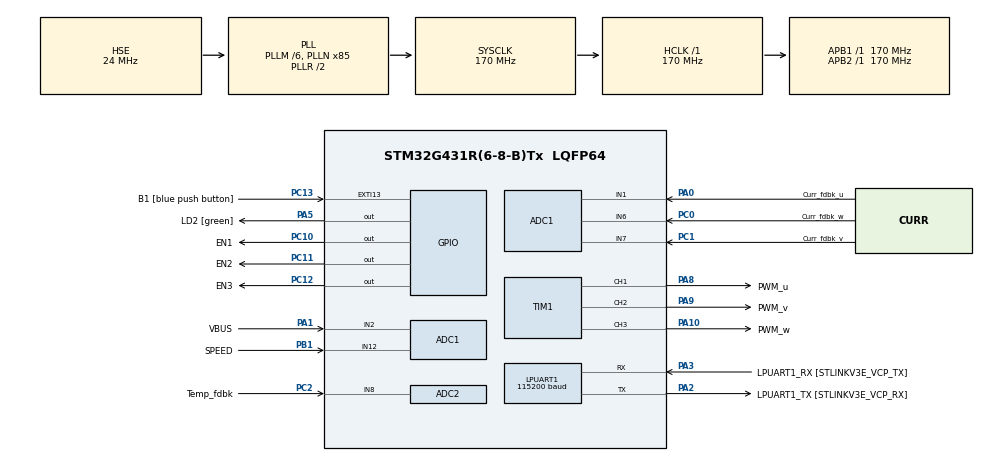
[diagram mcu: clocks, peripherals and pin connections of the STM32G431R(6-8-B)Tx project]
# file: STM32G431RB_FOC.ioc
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ADC1.Channel-0\#ChannelRegularConversion=ADC_CHANNEL_1
ADC1.EnableInjectedConversion=ENABLE
ADC1.ExternalTrigInjecConv=ADC_EXTERNALTRIGINJEC_T1_TRGO
ADC1.InjNumberOfConversion=3
ADC1.InjectedChannel-1\#ChannelInjectedConversion=ADC_CHANNEL_1
ADC1.InjectedChannel-2\#ChannelInjectedConversion=ADC_CHANNEL_7
ADC1.InjectedChannel-3\#ChannelInjectedConversion=ADC_CHANNEL_6
ADC1.InjectedOffsetNumber-1\#ChannelInjectedConversion=ADC_OFFSET_NONE
ADC1.InjectedOffsetNumber-2\#ChannelInjectedConversion=ADC_OFFSET_NONE
ADC1.InjectedOffsetNumber-3\#ChannelInjectedConversion=ADC_OFFSET_NONE
ADC1.InjectedRank-1\#ChannelInjectedConversion=1
ADC1.InjectedRank-2\#ChannelInjectedConversion=2
ADC1.InjectedRank-3\#ChannelInjectedConversion=3
ADC1.InjectedSamplingTime-1\#ChannelInjectedConversion=ADC_SAMPLETIME_2CYCLES_5
ADC1.InjectedSamplingTime-2\#ChannelInjectedConversion=ADC_SAMPLETIME_2CYCLES_5
ADC1.InjectedSamplingTime-3\#ChannelInjectedConversion=ADC_SAMPLETIME_2CYCLES_5
ADC1.NbrOfConversionFlag=1
ADC1.OffsetNumber-0\#ChannelRegularConversion=ADC_OFFSET_NONE
ADC1.Rank-0\#ChannelRegularConversion=1
ADC1.Rank1_Channel=ADC_CHANNEL_1
ADC1.Rank2_Channel=ADC_CHANNEL_7
ADC1.Rank3_Channel=ADC_CHANNEL_6
ADC1.SamplingTime-0\#ChannelRegularConversion=ADC_SAMPLETIME_2CYCLES_5
ADC1.master=1
ADC2.Channel-0\#ChannelRegularConversion=ADC_CHANNEL_8
ADC2.NbrOfConversionFlag=1
ADC2.OffsetNumber-0\#ChannelRegularConversion=ADC_OFFSET_NONE
ADC2.Rank-0\#ChannelRegularConversion=1
ADC2.SamplingTime-0\#ChannelRegularConversion=ADC_SAMPLETIME_2CYCLES_5
LPUART1.BaudRate=115200
LPUART1.WordLength=UART_WORDLENGTH_8B
Mcu.Family=STM32G4
Mcu.Name=STM32G431R(6-8-B)Tx
Mcu.Package=LQFP64
NVIC.PriorityGroup=NVIC_PRIORITYGROUP_4
PA0.GPIO_Label=Curr_fdbk_u
PA0.Mode=IN1-Single-Ended
PA0.Signal=ADC1_IN1
PA1.GPIO_Label=VBUS
PA1.Mode=IN2-Single-Ended
PA1.Signal=ADC1_IN2
PA10.GPIO_Label=PWM_w
PA10.Signal=S_TIM1_CH3
PA13.GPIO_Label=T_SWDIO
PA13.Mode=Serial_Wire
PA13.Signal=SYS_JTMS-SWDIO
PA14.GPIO_Label=T_SWCLK
PA14.Mode=Serial_Wire
PA14.Signal=SYS_JTCK-SWCLK
PA2.GPIO_Label=LPUART1_TX [STLINKV3E_VCP_RX]
PA2.Mode=Asynchronous
PA2.Signal=LPUART1_TX
PA3.GPIO_Label=LPUART1_RX [STLINKV3E_VCP_TX]
PA3.Mode=Asynchronous
PA3.Signal=LPUART1_RX
PA5.GPIO_Label=LD2 [green]
PA5.Signal=GPIO_Output
PA8.GPIO_Label=PWM_u
PA8.Signal=S_TIM1_CH1
PA9.GPIO_Label=PWM_v
PA9.Signal=S_TIM1_CH2
PB1.GPIO_Label=SPEED
PB1.Mode=IN12-Single-Ended
PB1.Signal=ADC1_IN12
PB3.GPIO_Label=T_SWO
PB3.Signal=SYS_JTDO-SWO
PC0.GPIO_Label=Curr_fdbk_w
PC0.Mode=IN6-Single-Ended
PC0.Signal=ADC1_IN6
PC1.GPIO_Label=Curr_fdbk_v
PC1.Mode=IN7-Single-Ended
PC1.Signal=ADC1_IN7
PC10.GPIO_Label=EN1
PC10.Signal=GPIO_Output
PC11.GPIO_Label=EN2
PC11.Signal=GPIO_Output
PC12.GPIO_Label=EN3
PC12.Signal=GPIO_Output
PC13.GPIO_Label=B1 [blue push button]
PC13.Signal=GPXTI13
PC14-OSC32_IN.Mode=LSE-External-Oscillator
PC14-OSC32_IN.Signal=RCC_OSC32_IN
PC15-OSC32_OUT.Mode=LSE-External-Oscillator
PC15-OSC32_OUT.Signal=RCC_OSC32_OUT
PC2.GPIO_Label=Temp_fdbk
PC2.Mode=IN8-Single-Ended
PC2.Signal=ADC2_IN8
PF0-OSC_IN.Mode=HSE-External-Oscillator
PF0-OSC_IN.Signal=RCC_OSC_IN
PF1-OSC_OUT.Mode=HSE-External-Oscillator
PF1-OSC_OUT.Signal=RCC_OSC_OUT
ProjectManager.HeapSize=0x200
ProjectManager.StackSize=0x400
ProjectManager.TargetToolchain=Makefile
RCC.ADC12Freq_Value=170000000
RCC.AHBFreq_Value=170000000
RCC.APB1Freq_Value=170000000
RCC.APB1TimFreq_Value=170000000
RCC.APB2Freq_Value=170000000
RCC.APB2TimFreq_Value=170000000
RCC.CortexFreq_Value=170000000
RCC.EXTERNAL_CLOCK_VALUE=12288000
RCC.HCLKFreq_Value=170000000
RCC.HSE_VALUE=24000000
RCC.HSI48_VALUE=48000000
RCC.HSI_VALUE=16000000
RCC.PLLM=RCC_PLLM_DIV6
RCC.PLLN=85
RCC.PLLSourceVirtual=RCC_PLLSOURCE_HSE
RCC.RTCClockSelection=RCC_RTCCLKSOURCE_LSE
RCC.SYSCLKFreq_VALUE=170000000
RCC.SYSCLKSource=RCC_SYSCLKSOURCE_PLLCLK
RCC.USBFreq_Value=170000000
RCC.VCOOutputFreq_Value=340000000
SH.S_TIM1_CH1.0=TIM1_CH1,Output Compare1 CH1
SH.S_TIM1_CH2.0=TIM1_CH2,Output Compare2 CH2
SH.S_TIM1_CH3.0=TIM1_CH3,Output Compare3 CH3
TIM1.Channel-Output\ Compare1\ CH1=TIM_CHANNEL_1
TIM1.Channel-Output\ Compare2\ CH2=TIM_CHANNEL_2
TIM1.Channel-Output\ Compare3\ CH3=TIM_CHANNEL_3
VP_SYS_VS_DBSignals.Mode=DisableDeadBatterySignals
board=NUCLEO-G431RB

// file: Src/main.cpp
/* USER CODE BEGIN Header */
/**
  ******************************************************************************
  * @file           : main.c
  * @brief          : Main program body
  ******************************************************************************
  * @attention
  *
  * <h2><center>&copy; Copyright (c) 2020 STMicroelectronics.
  * All rights reserved.</center></h2>
  *
  * This software component is licensed by ST under BSD 3-Clause license,
  * the "License"; You may not use this file except in compliance with the
  * License. You may obtain a copy of the License at:
  *                        opensource.org/licenses/BSD-3-Clause
  *
  ******************************************************************************
  */
/* USER CODE END Header */

#include "main.h"
#include "adc.h"
#include "usart.h"
#include "tim.h"
#include "gpio.h"

#include "InterruptHandler.hpp"
#include "MotorCtrlMain.hpp"

void SystemClock_Config(void);

int main(void)
{

  /* MCU Configuration--------------------------------------------------------*/

  /* Reset of all peripherals, Initializes the Flash interface and the Systick. */
  HAL_Init();

  /* Configure the system clock */
  SystemClock_Config();

  /* Initialize all configured peripherals */
  MX_GPIO_Init();
  MX_LPUART1_UART_Init();
  MX_ADC1_Init();
  MX_TIM1_Init();
  MX_ADC2_Init();
  /* USER CODE BEGIN 2 */

	MotorCtrlMain mMotorCtrlMain;
	std::function<void()> func = [&](){ return mMotorCtrlMain.MotorCtrl(); };
	InterruptHandler::GetInstance().SetADCCpltInterrptFunc(func);
	mMotorCtrlMain.MotorCtrlInit();

//    TIM1 -> PSC = 17000;
//    TIM1 -> ARR = 10000;

  /* USER CODE END 2 */

  /* Infinite loop */
  while (1)
  {
	  asm("NOP");
  }
}

void SystemClock_Config(void)
{
  RCC_OscInitTypeDef RCC_OscInitStruct = {0};
  RCC_ClkInitTypeDef RCC_ClkInitStruct = {0};
  RCC_PeriphCLKInitTypeDef PeriphClkInit = {0};

  /** Configure the main internal regulator output voltage
  */
  HAL_PWREx_ControlVoltageScaling(PWR_REGULATOR_VOLTAGE_SCALE1_BOOST);
  /** Initializes the CPU, AHB and APB busses clocks
  */
  RCC_OscInitStruct.OscillatorType = RCC_OSCILLATORTYPE_HSE;
  RCC_OscInitStruct.HSEState = RCC_HSE_ON;
  RCC_OscInitStruct.PLL.PLLState = RCC_PLL_ON;
  RCC_OscInitStruct.PLL.PLLSource = RCC_PLLSOURCE_HSE;
  RCC_OscInitStruct.PLL.PLLM = RCC_PLLM_DIV6;
  RCC_OscInitStruct.PLL.PLLN = 85;
  RCC_OscInitStruct.PLL.PLLP = RCC_PLLP_DIV2;
  RCC_OscInitStruct.PLL.PLLQ = RCC_PLLQ_DIV2;
  RCC_OscInitStruct.PLL.PLLR = RCC_PLLR_DIV2;
  if (HAL_RCC_OscConfig(&RCC_OscInitStruct) != HAL_OK)
  {
    Error_Handler();
  }
  /** Initializes the CPU, AHB and APB busses clocks
  */
  RCC_ClkInitStruct.ClockType = RCC_CLOCKTYPE_HCLK|RCC_CLOCKTYPE_SYSCLK
                              |RCC_CLOCKTYPE_PCLK1|RCC_CLOCKTYPE_PCLK2;
  RCC_ClkInitStruct.SYSCLKSource = RCC_SYSCLKSOURCE_PLLCLK;
  RCC_ClkInitStruct.AHBCLKDivider = RCC_SYSCLK_DIV1;
  RCC_ClkInitStruct.APB1CLKDivider = RCC_HCLK_DIV1;
  RCC_ClkInitStruct.APB2CLKDivider = RCC_HCLK_DIV1;

  if (HAL_RCC_ClockConfig(&RCC_ClkInitStruct, FLASH_LATENCY_8) != HAL_OK)
  {
    Error_Handler();
  }
  /** Initializes the peripherals clocks
  */
  PeriphClkInit.PeriphClockSelection = RCC_PERIPHCLK_LPUART1|RCC_PERIPHCLK_ADC12;
  PeriphClkInit.Lpuart1ClockSelection = RCC_LPUART1CLKSOURCE_PCLK1;
  PeriphClkInit.Adc12ClockSelection = RCC_ADC12CLKSOURCE_SYSCLK;
  if (HAL_RCCEx_PeriphCLKConfig(&PeriphClkInit) != HAL_OK)
  {
    Error_Handler();
  }
}

void Error_Handler(void)
{
}

/************************ (C) COPYRIGHT STMicroelectronics *****END OF FILE****/
